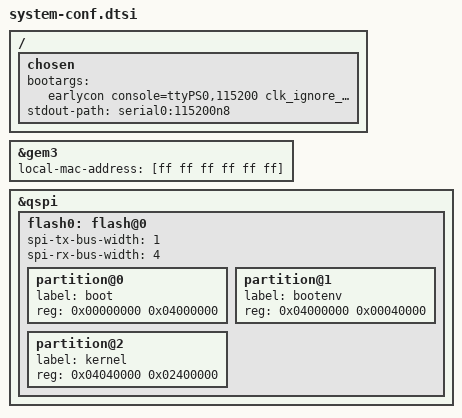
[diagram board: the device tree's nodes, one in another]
/*
 * CAUTION: This file is automatically generated by PetaLinux SDK.
 * DO NOT modify this file
 */


/ {
	chosen {
		bootargs = " earlycon console=ttyPS0,115200 clk_ignore_unused init_fatal_sh=1";
		stdout-path = "serial0:115200n8";
	};
};

&gem3 {
	local-mac-address = [ff ff ff ff ff ff];
};

&qspi {
	#address-cells = <1>;
	#size-cells = <0>;
	flash0: flash@0 {
		spi-tx-bus-width=<1>;
		spi-rx-bus-width=<4>;
		/delete-node/ partition@0;
		/delete-node/ partition@100000;
		/delete-node/ partition@600000;
		/delete-node/ partition@620000;
		/delete-node/ partition@c00000;
		partition@0 {
			label = "boot";
			reg = <0x00000000 0x04000000>;
		};
		partition@1 {
			label = "bootenv";
			reg = <0x04000000 0x00040000>;
		};
		partition@2 {
			label = "kernel";
			reg = <0x04040000 0x02400000>;
		};
	};
};

